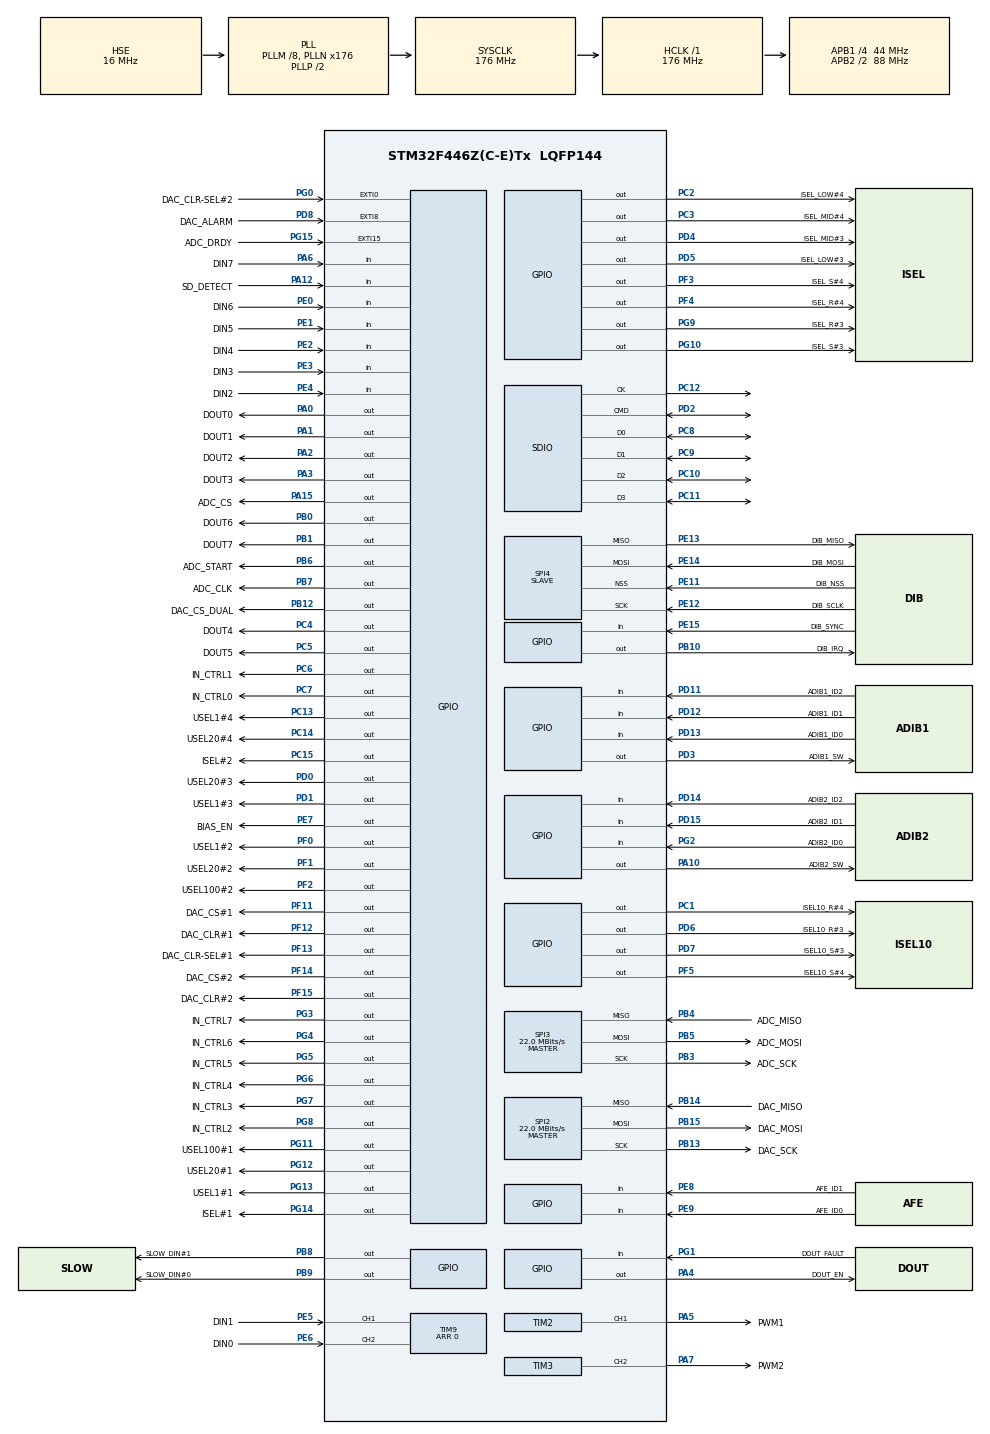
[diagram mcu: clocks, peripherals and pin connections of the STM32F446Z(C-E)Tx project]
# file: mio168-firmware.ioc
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Dma.SDIO_RX.4.MemBurst=DMA_MBURST_INC4
PD12.GPIO_Label=ADIB1_ID1
FATFS._USE_LFN=2
FATFS0.BSP.api=Unknown
NVIC.TIM6_DAC_IRQn=true\:0\:0\:false\:false\:true\:true\:true
PF14.PinState=GPIO_PIN_SET
PG8.Signal=GPIO_Output
Dma.SPI4_TX.1.PeriphDataAlignment=DMA_PDATAALIGN_BYTE
PG0.Signal=GPXTI0
PG15.GPIO_Label=ADC_DRDY
RCC.APB2TimFreq_Value=176000000
PB6.Signal=GPIO_Output
PC7.Signal=GPIO_Output
PB12.PinState=GPIO_PIN_SET
PD0.Signal=GPIO_Output
Dma.SPI3_RX.6.Direction=DMA_PERIPH_TO_MEMORY
PD8.Signal=GPXTI8
PE1.Signal=GPIO_Input
Dma.SPI4_RX.0.Priority=DMA_PRIORITY_LOW
FATFS0.BSP.ip=GPIO
NVIC.EXTI15_10_IRQn=true\:0\:0\:false\:false\:true\:true\:true
Dma.SPI2_RX.2.MemDataAlignment=DMA_MDATAALIGN_HALFWORD
Dma.SPI3_RX.6.Mode=DMA_NORMAL
PB3.Mode=Full_Duplex_Master
PF1.GPIO_Label=USEL20\#2
Dma.SPI2_RX.2.PeriphInc=DMA_PINC_DISABLE
PD1.GPIO_Label=USEL1\#3
PB12.GPIO_Label=DAC_CS_DUAL
PF12.GPIO_Label=DAC_CLR\#1
PC4.GPIO_Label=DOUT4
PE9.Signal=GPIO_Input
PB14.Mode=Full_Duplex_Master
PB1.GPIO_Label=DOUT7
PG4.GPIO_Label=IN_CTRL6
PE4.GPIO_Label=DIN2
PC9.Mode=SD_4_bits_Wide_bus
Dma.SPI2_RX.2.PeriphDataAlignment=DMA_PDATAALIGN_HALFWORD
PD14.GPIO_PuPd=GPIO_PULLUP
PE13.Mode=Full_Duplex_Slave
PG0.GPIO_PuPd=GPIO_PULLUP
Dma.SDIO_TX.5.PeriphDataAlignment=DMA_PDATAALIGN_WORD
Mcu.Package=LQFP144
PB9.Signal=GPIO_Output
PB1.Signal=GPIO_Output
SPI2.Mode=SPI_MODE_MASTER
Dma.SPI3_RX.6.MemInc=DMA_MINC_ENABLE
SPI3.Mode=SPI_MODE_MASTER
PD12.Signal=GPIO_Input
PA10.Signal=GPIO_Output
PE12.GPIO_Label=DIB_SCLK
TIM7.AutoReloadPreload=TIM_AUTORELOAD_PRELOAD_ENABLE
PC11.Mode=SD_4_bits_Wide_bus
RCC.APB2CLKDivider=RCC_HCLK_DIV2
Dma.SDIO_RX.4.PeriphDataAlignment=DMA_PDATAALIGN_WORD
RCC.APB1TimFreq_Value=88000000
PB13.Mode=Full_Duplex_Master
PA4.GPIO_Label=DOUT_EN
PD15.Signal=GPIO_Input
PG12.Signal=GPIO_Output
PE12.Mode=Full_Duplex_Slave
FATFS0.BSP.STBoard=false
Dma.SPI3_TX.7.MemInc=DMA_MINC_ENABLE
PG5.Signal=GPIO_Output
PC13.Signal=GPIO_Output
FATFS0.BSP.mode=Input
PD3.Signal=GPIO_Output
PC2.Signal=GPIO_Output
Dma.SDIO_TX.5.Direction=DMA_MEMORY_TO_PERIPH
PC14-OSC32_IN.Signal=GPIO_Output
Dma.SPI2_TX.3.PeriphDataAlignment=DMA_PDATAALIGN_HALFWORD
PB8.GPIO_Label=SLOW_DIN\#1
PE8.GPIO_Label=AFE_ID1
SDIO.ClockDiv=3
NVIC.DMA2_Stream6_IRQn=true\:0\:0\:false\:false\:true\:false\:true
PB14.Signal=SPI2_MISO
PA5.Signal=S_TIM2_CH1_ETR
PC12.Mode=SD_4_bits_Wide_bus
PE1.GPIO_Label=DIN5
PE14.Signal=SPI4_MOSI
PB4.GPIO_Label=ADC_MISO
PB15.GPIO_Label=DAC_MOSI
PG15.GPIO_ModeDefaultEXTI=GPIO_MODE_IT_FALLING
PG7.GPIO_Label=IN_CTRL3
PF4.GPIO_Label=ISEL_R\#4
PA1.GPIO_Label=DOUT1
SH.S_TIM9_CH1.0=TIM9_CH1,Input_Capture1_from_TI1
PF13.Signal=GPIO_Output
TIM2.Period=0
PC7.GPIO_Label=IN_CTRL0
PC8.Mode=SD_4_bits_Wide_bus
Dma.SDIO_RX.4.PeriphInc=DMA_PINC_DISABLE
PA5.GPIO_Label=PWM1
Dma.SDIO_RX.4.FIFOThreshold=DMA_FIFO_THRESHOLD_FULL
PE5.GPIO_Label=DIN1
ProjectManager.HeapSize=0x2000
NVIC.PriorityGroup=NVIC_PRIORITYGROUP_4
PF0.GPIO_Label=USEL1\#2
SDIO.HardwareFlowControl=SDIO_HARDWARE_FLOW_CONTROL_ENABLE
PE3.Signal=GPIO_Input
PF4.Signal=GPIO_Output
TIM9.Channel-Input_Capture2_from_TI2=TIM_CHANNEL_2
PD2.Signal=SDIO_CMD
FATFS0.BSP.name=Detect_SDIO
Mcu.Family=STM32F4
Dma.SDIO_TX.5.MemInc=DMA_MINC_ENABLE
PB10.PinState=GPIO_PIN_SET
Dma.SPI4_TX.1.MemDataAlignment=DMA_MDATAALIGN_BYTE
PG2.Signal=GPIO_Input
PE11.GPIO_Label=DIB_NSS
PD0.GPIO_Label=USEL20\#3
Dma.SPI3_TX.7.Priority=DMA_PRIORITY_LOW
PB13.GPIO_Label=DAC_SCK
PD8.GPIO_PuPd=GPIO_PULLUP
PG5.GPIO_Label=IN_CTRL5
Dma.SPI3_TX.7.FIFOMode=DMA_FIFOMODE_DISABLE
PB15.Signal=SPI2_MOSI
PG11.Signal=GPIO_Output
PG15.Signal=GPXTI15
Dma.SDIO_TX.5.FIFOThreshold=DMA_FIFO_THRESHOLD_FULL
PD13.Signal=GPIO_Input
Dma.SPI3_TX.7.Instance=DMA1_Stream5
PA15.GPIO_Label=ADC_CS
Dma.SDIO_RX.4.FIFOMode=DMA_FIFOMODE_ENABLE
TIM3.Period=0
PF13.GPIO_Speed=GPIO_SPEED_FREQ_VERY_HIGH
Dma.SPI4_TX.1.Direction=DMA_MEMORY_TO_PERIPH
TIM7.Period=999
Dma.SDIO_RX.4.MemDataAlignment=DMA_MDATAALIGN_WORD
Dma.SPI2_RX.2.Instance=DMA1_Stream3
RCC.HSE_VALUE=16000000
PA0-WKUP.GPIO_Speed=GPIO_SPEED_FREQ_LOW
RCC.RCC_MCO1Source=RCC_MCO1SOURCE_PLLCLK
PA14.Mode=Serial_Wire
PF11.Signal=GPIO_Output
PB5.Mode=Full_Duplex_Master
PB7.Signal=GPIO_Output
Dma.SDIO_RX.4.Mode=DMA_PFCTRL
TIM2.Channel-PWM\ Generation1\ CH1=TIM_CHANNEL_1
TIM7.TIM_MasterOutputTrigger=TIM_TRGO_RESET
PH1-OSC_OUT.Mode=HSE-External-Oscillator
PB7.GPIO_Label=ADC_CLK
PD13.GPIO_Label=ADIB1_ID0
PA6.Signal=GPIO_Input
PD5.GPIO_Label=ISEL_LOW\#3
PG1.GPIO_PuPd=GPIO_PULLUP
PA15.Signal=GPIO_Output
PG0.GPIO_Label=DAC_CLR-SEL\#2
Dma.SDIO_RX.4.Direction=DMA_PERIPH_TO_MEMORY
PB5.GPIO_Label=ADC_MOSI
Dma.Request2=SPI2_RX
Dma.Request1=SPI4_TX
Dma.Request4=SDIO_RX
Dma.Request3=SPI2_TX
Dma.SDIO_RX.4.Priority=DMA_PRIORITY_LOW
Dma.Request6=SPI3_RX
Dma.Request5=SDIO_TX
NVIC.DMA1_Stream0_IRQn=true\:0\:0\:true\:false\:true\:false\:true
PG11.GPIO_Label=USEL100\#1
PC5.Signal=GPIO_Output
PD3.GPIO_Label=ADIB1_SW
Dma.Request7=SPI3_TX
PE7.Signal=GPIO_Output
PD6.Signal=GPIO_Output
Dma.Request0=SPI4_RX
PF3.GPIO_Label=ISEL_S\#4
PE2.GPIO_Label=DIN4
Dma.SPI2_TX.3.Direction=DMA_MEMORY_TO_PERIPH
PB4.Signal=SPI3_MISO
PG2.GPIO_Label=ADIB2_ID0
PA3.Signal=GPIO_Output
Dma.SPI4_TX.1.MemInc=DMA_MINC_ENABLE
Dma.SDIO_TX.5.Mode=DMA_PFCTRL
Dma.SPI3_RX.6.FIFOMode=DMA_FIFOMODE_DISABLE
PD15.GPIO_Label=ADIB2_ID1
PG7.Signal=GPIO_Output
Dma.SPI2_TX.3.MemDataAlignment=DMA_MDATAALIGN_HALFWORD
PC11.Signal=SDIO_D3
PC8.Signal=SDIO_D0
TIM6.Prescaler=8
PC10.Mode=SD_4_bits_Wide_bus
VP_TIM6_VS_ClockSourceINT.Mode=Enable_Timer
PE14.GPIO_Label=DIB_MOSI
PA12.GPIO_Label=SD_DETECT
NVIC.SDIO_IRQn=true\:0\:0\:false\:false\:true\:true\:true
Dma.SDIO_RX.4.Instance=DMA2_Stream3
Dma.SPI2_RX.2.Mode=DMA_CIRCULAR
PD8.GPIO_Label=DAC_ALARM
FATFS0.BSP.instance=PA12
PG8.GPIO_Label=IN_CTRL2
PA13.Signal=SYS_JTMS-SWDIO
PB10.GPIO_Label=DIB_IRQ
Dma.SPI4_RX.0.PeriphDataAlignment=DMA_PDATAALIGN_BYTE
RCC.USBFreq_Value=25000000
PA1.Signal=GPIO_Output
PD2.Mode=SD_4_bits_Wide_bus
TIM7.Prescaler=8
board=custom
SPI3.CLKPhase=SPI_PHASE_2EDGE
RCC.VCOOutputFreq_Value=352000000
PB15.Mode=Full_Duplex_Master
Dma.SPI3_RX.6.PeriphDataAlignment=DMA_PDATAALIGN_BYTE
PA15.PinState=GPIO_PIN_SET
PC1.GPIO_Label=ISEL10_R\#4
PF15.GPIO_Label=DAC_CLR\#2
PF1.Signal=GPIO_Output
PE0.Signal=GPIO_Input
PE7.GPIO_Label=BIAS_EN
PE12.Signal=SPI4_SCK
RCC.SYSCLKFreq_VALUE=176000000
Dma.SPI3_RX.6.Instance=DMA1_Stream0
Dma.SPI4_RX.0.Direction=DMA_PERIPH_TO_MEMORY
PA15.GPIO_Speed=GPIO_SPEED_FREQ_LOW
Dma.SDIO_TX.5.FIFOMode=DMA_FIFOMODE_ENABLE
RCC.PLLQ=8
RCC.PLLM=8
RCC.PLLN=176
Dma.SPI3_TX.7.PeriphInc=DMA_PINC_DISABLE
NVIC.DMA1_Stream3_IRQn=true\:0\:0\:false\:false\:true\:false\:false
Dma.SDIO_RX.4.PeriphBurst=DMA_PBURST_INC4
VP_CRC_VS_CRC.Mode=CRC_Activate
Dma.SDIO_TX.5.Instance=DMA2_Stream6
PB12.Signal=GPIO_Output
PA3.GPIO_Label=DOUT3
Dma.SPI3_TX.7.PeriphDataAlignment=DMA_PDATAALIGN_BYTE
PH0-OSC_IN.Signal=RCC_OSC_IN
SPI3.Direction=SPI_DIRECTION_2LINES
SPI4.VirtualType=VM_SLAVE
SPI3.VirtualType=VM_MASTER
PG2.GPIO_PuPd=GPIO_PULLUP
SPI2.VirtualType=VM_MASTER
VP_FATFS_VS_SDIO.Mode=SDIO
PG4.Signal=GPIO_Output
PC12.Signal=SDIO_CK
PB14.GPIO_Label=DAC_MISO
PG6.GPIO_Label=IN_CTRL4
PE8.GPIO_PuPd=GPIO_PULLUP
PC6.GPIO_Label=IN_CTRL1
PA6.GPIO_Label=DIN7
PB6.GPIO_Label=ADC_START
PB13.Signal=SPI2_SCK
PD6.GPIO_Label=ISEL10_R\#3
PG13.Signal=GPIO_Output
PC15-OSC32_OUT.GPIO_Label=ISEL\#2
PE6.GPIO_Label=DIN0
RCC.SYSCLKSource=RCC_SYSCLKSOURCE_PLLCLK
Dma.SPI3_RX.6.PeriphInc=DMA_PINC_DISABLE
Dma.SPI3_TX.7.MemDataAlignment=DMA_MDATAALIGN_BYTE
Dma.SPI2_RX.2.Direction=DMA_PERIPH_TO_MEMORY
PD4.Signal=GPIO_Output
PC3.Signal=GPIO_Output
PE5.Signal=S_TIM9_CH1
FATFS0.BSP.i2caddr=0
SPI2.CalculateBaudRate=22.0 MBits/s
PE2.Signal=GPIO_Input
PF3.Signal=GPIO_Output
Dma.SPI4_RX.0.Mode=DMA_NORMAL
PB7.PinState=GPIO_PIN_SET
FATFS0.BSP.solution=PA12
Dma.SPI2_RX.2.MemInc=DMA_MINC_ENABLE
Dma.SDIO_TX.5.PeriphInc=DMA_PINC_DISABLE
PF14.Signal=GPIO_Output
PA12.GPIO_PuPd=GPIO_PULLUP
TIM9.Period=0
Dma.SPI2_TX.3.MemInc=DMA_MINC_ENABLE
Dma.SPI3_RX.6.Priority=DMA_PRIORITY_LOW
Dma.SPI3_TX.7.Direction=DMA_MEMORY_TO_PERIPH
Dma.SDIO_TX.5.MemDataAlignment=DMA_MDATAALIGN_WORD
PG9.Signal=GPIO_Output
PC6.Signal=GPIO_Output
PD7.Signal=GPIO_Output
PD1.Signal=GPIO_Output
PF14.GPIO_Label=DAC_CS\#2
PF13.PinState=GPIO_PIN_SET
NVIC.DMA2_Stream1_IRQn=true\:0\:0\:true\:false\:true\:false\:true
RCC.APB1CLKDivider=RCC_HCLK_DIV4
Dma.SPI3_RX.6.MemDataAlignment=DMA_MDATAALIGN_BYTE
PF13.GPIO_Label=DAC_CLR-SEL\#1
PG13.GPIO_Label=USEL1\#1
PA0-WKUP.GPIO_Label=DOUT0
PA0-WKUP.Signal=GPIO_Output
PG10.Signal=GPIO_Output
Dma.SPI4_TX.1.PeriphInc=DMA_PINC_DISABLE
Dma.SPI2_RX.2.FIFOMode=DMA_FIFOMODE_DISABLE
SH.S_TIM9_CH2.0=TIM9_CH2,Input_Capture2_from_TI2
Dma.SPI3_TX.7.Mode=DMA_NORMAL
SPI2.CRCCalculation=SPI_CRCCALCULATION_DISABLE
Dma.SPI2_TX.3.Mode=DMA_CIRCULAR
SPI4.VirtualNSS=VM_NSSHARD
PE9.GPIO_Label=AFE_ID0
Dma.SDIO_TX.5.Priority=DMA_PRIORITY_LOW
PB10.Signal=GPIO_Output
FATFS.BSP.number=1
RCC.USBCLockSelection=RCC_CLK48CLKSOURCE_PLLSAIP
Dma.SPI2_TX.3.Instance=DMA1_Stream4
PE15.Signal=GPIO_Input
PE8.Signal=GPIO_Input
PA13.Mode=Serial_Wire
PG14.GPIO_Label=ISEL\#1
PA4.Signal=GPIO_Output
PB5.Signal=SPI3_MOSI
PE13.GPIO_Label=DIB_MISO
PD11.Signal=GPIO_Input
SH.S_TIM2_CH1_ETR.0=TIM2_CH1,PWM Generation1 CH1
Dma.SDIO_TX.5.MemBurst=DMA_MBURST_INC4
Dma.SPI4_TX.1.Priority=DMA_PRIORITY_LOW
TIM3.Channel-PWM\ Generation2\ CH2=TIM_CHANNEL_2
Dma.SPI2_TX.3.PeriphInc=DMA_PINC_DISABLE
PC3.GPIO_Label=ISEL_MID\#4
SPI2.DataSize=SPI_DATASIZE_8BIT
Dma.SPI2_TX.3.FIFOMode=DMA_FIFOMODE_DISABLE
PG3.GPIO_Label=IN_CTRL7
PB0.Signal=GPIO_Output
Dma.SPI4_RX.0.MemDataAlignment=DMA_MDATAALIGN_BYTE
PC1.Signal=GPIO_Output
PG15.GPIO_PuPd=GPIO_PULLUP
PG10.GPIO_Label=ISEL_S\#3
RCC.CortexFreq_Value=176000000
PG6.Signal=GPIO_Output
PC10.Signal=SDIO_D2
SPI4.Direction=SPI_DIRECTION_2LINES
PB0.GPIO_Label=DOUT6
PC13.GPIO_Label=USEL1\#4
NVIC.DMA1_Stream4_IRQn=true\:0\:0\:false\:false\:true\:false\:false
ProjectManager.StackSize=0x4000
VP_TIM7_VS_ClockSourceINT.Mode=Enable_Timer
PD11.GPIO_PuPd=GPIO_PULLUP
Dma.SPI4_RX.0.MemInc=DMA_MINC_ENABLE
PA12.Signal=GPIO_Input
PE11.Mode=NSS_Signal_Hard_Input
SPI4.Mode=SPI_MODE_SLAVE
PD11.GPIO_Label=ADIB1_ID2
RCC.HCLKFreq_Value=176000000
PF11.GPIO_Label=DAC_CS\#1
PF12.Signal=GPIO_Output
Dma.SPI2_TX.3.Priority=DMA_PRIORITY_LOW
NVIC.DMA2_Stream0_IRQn=true\:0\:0\:true\:false\:true\:false\:true
RCC.AHBFreq_Value=176000000
SPI2.BaudRatePrescaler=SPI_BAUDRATEPRESCALER_2
PH0-OSC_IN.Mode=HSE-External-Oscillator
SPI3.DataSize=SPI_DATASIZE_8BIT
SPI4.CRCPolynomial=X0+X1+X2
PB4.Mode=Full_Duplex_Master
PE13.Signal=SPI4_MISO
PA10.GPIO_Label=ADIB2_SW
Dma.SPI4_TX.1.Instance=DMA2_Stream1
PF11.PinState=GPIO_PIN_SET
RCC.RCC_MCODiv1=RCC_MCODIV_4
TIM6.Period=999
PE4.Signal=GPIO_Input
PD7.GPIO_Label=ISEL10_S\#3
Dma.SPI2_RX.2.Priority=DMA_PRIORITY_LOW
PA2.GPIO_Label=DOUT2
PD15.GPIO_PuPd=GPIO_PULLUP
PF5.GPIO_Label=ISEL10_S\#4
SPI2.CLKPhase=SPI_PHASE_1EDGE
PE0.GPIO_Label=DIN6
RCC.PLLSAIN=50
PF5.Signal=GPIO_Output
RCC.PLLSAIM=8
RCC.PLLSAIP=RCC_PLLSAIP_DIV4
Dma.SPI4_RX.0.PeriphInc=DMA_PINC_DISABLE
PC14-OSC32_IN.GPIO_Label=USEL20\#4
SPI2.Direction=SPI_DIRECTION_2LINES
PF0.Signal=GPIO_Output
PC2.GPIO_Label=ISEL_LOW\#4
NVIC.TIM7_IRQn=true\:0\:0\:true\:false\:true\:true\:true
PB3.GPIO_Label=ADC_SCK
RCC.PLLSourceVirtual=RCC_PLLSOURCE_HSE
Dma.SPI4_TX.1.Mode=DMA_NORMAL
PB9.GPIO_Label=SLOW_DIN\#0
PG3.Signal=GPIO_Output
PG1.Signal=GPIO_Input
PC4.Signal=GPIO_Output
PD5.Signal=GPIO_Output
SDIO.ClockBypass=SDIO_CLOCK_BYPASS_ENABLE
Dma.SDIO_RX.4.MemInc=DMA_MINC_ENABLE
TIM6.AutoReloadPreload=TIM_AUTORELOAD_PRELOAD_ENABLE
Dma.SPI4_TX.1.FIFOMode=DMA_FIFOMODE_DISABLE
PE15.GPIO_Label=DIB_SYNC
ProjectManager.TargetToolchain=STM32CubeIDE
NVIC.DMA1_Stream5_IRQn=true\:0\:0\:true\:false\:true\:false\:true
PF2.Signal=GPIO_Output
NVIC.DMA2_Stream3_IRQn=true\:0\:0\:false\:false\:true\:false\:true
PE11.Signal=SPI4_NSS
PC15-OSC32_OUT.Signal=GPIO_Output
TIM9.Channel-Input_Capture1_from_TI1=TIM_CHANNEL_1
SPI4.CRCCalculation=SPI_CRCCALCULATION_ENABLE
PG9.GPIO_Label=ISEL_R\#3
SH.S_TIM3_CH2.0=TIM3_CH2,PWM Generation2 CH2
PG14.Signal=GPIO_Output
PG1.GPIO_Label=DOUT_FAULT
RCC.APB2Freq_Value=88000000
SPI3.CalculateBaudRate=22.0 MBits/s
PD4.GPIO_Label=ISEL_MID\#3
PE14.Mode=Full_Duplex_Slave
SPI3.BaudRatePrescaler=SPI_BAUDRATEPRESCALER_2
PH1-OSC_OUT.Signal=RCC_OSC_OUT
PD13.GPIO_PuPd=GPIO_PULLUP
PF15.Signal=GPIO_Output
PD14.GPIO_Label=ADIB2_ID2
PE6.Signal=S_TIM9_CH2
Mcu.Name=STM32F446Z(C-E)Tx
PA2.Signal=GPIO_Output
PD14.Signal=GPIO_Input
PB3.Signal=SPI3_SCK
PA7.GPIO_Label=PWM2
Dma.SDIO_TX.5.PeriphBurst=DMA_PBURST_INC4
PC5.GPIO_Label=DOUT5
Dma.SPI4_RX.0.Instance=DMA2_Stream0
PA14.Signal=SYS_JTCK-SWCLK
PG12.GPIO_Label=USEL20\#1
PB8.Signal=GPIO_Output
PE3.GPIO_Label=DIN3
PC9.Signal=SDIO_D1
RCC.APB1Freq_Value=44000000
SPI2.TIMode=SPI_TIMODE_DISABLE
PD12.GPIO_PuPd=GPIO_PULLUP
PA7.Signal=S_TIM3_CH2
PE9.GPIO_PuPd=GPIO_PULLUP
PF2.GPIO_Label=USEL100\#2
Dma.SPI4_RX.0.FIFOMode=DMA_FIFOMODE_DISABLE

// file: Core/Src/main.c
/* USER CODE BEGIN Header */
/**
  ******************************************************************************
  * @file           : main.c
  * @brief          : Main program body
  ******************************************************************************
  * @attention
  *
  * <h2><center>&copy; Copyright (c) 2020 STMicroelectronics.
  * All rights reserved.</center></h2>
  *
  * This software component is licensed by ST under BSD 3-Clause license,
  * the "License"; You may not use this file except in compliance with the
  * License. You may obtain a copy of the License at:
  *                        opensource.org/licenses/BSD-3-Clause
  *
  ******************************************************************************
  */
/* USER CODE END Header */
#include "main.h"
#include "fatfs.h"

/* USER CODE BEGIN Includes */
#include <stdio.h>
#include <string.h>

/* USER CODE END Includes */

CRC_HandleTypeDef hcrc;

SD_HandleTypeDef hsd;
DMA_HandleTypeDef hdma_sdio_rx;
DMA_HandleTypeDef hdma_sdio_tx;

SPI_HandleTypeDef hspi2;
SPI_HandleTypeDef hspi3;
SPI_HandleTypeDef hspi4;
DMA_HandleTypeDef hdma_spi2_rx;
DMA_HandleTypeDef hdma_spi2_tx;
DMA_HandleTypeDef hdma_spi3_rx;
DMA_HandleTypeDef hdma_spi3_tx;
DMA_HandleTypeDef hdma_spi4_rx;
DMA_HandleTypeDef hdma_spi4_tx;

TIM_HandleTypeDef htim2;
TIM_HandleTypeDef htim3;
TIM_HandleTypeDef htim6;
TIM_HandleTypeDef htim7;
TIM_HandleTypeDef htim9;

void SystemClock_Config(void);
static void MX_GPIO_Init(void);
static void MX_DMA_Init(void);
static void MX_SDIO_SD_Init(void);
static void MX_SPI4_Init(void);
static void MX_CRC_Init(void);
static void MX_SPI2_Init(void);
static void MX_SPI3_Init(void);
static void MX_TIM9_Init(void);
static void MX_TIM6_Init(void);
static void MX_TIM2_Init(void);
static void MX_TIM3_Init(void);
static void MX_TIM7_Init(void);
/* USER CODE BEGIN PFP */

#if 0
char buffer[65536];

static void testSdCard(uint32_t chunkSize) {
	if (f_mount(&SDFatFS, (TCHAR const*)SDPath, 1) != FR_OK) {
		/* FatFs Initialization Error */
		return;
	}

	char filePath[128];

	sprintf(filePath, "BMRK%d.TXT", (int)chunkSize);

	if (f_open(&SDFile, filePath, FA_CREATE_ALWAYS | FA_WRITE) != FR_OK) {
		return;
	}

	for (int i = 0; i < chunkSize - 1; i++) {
		buffer[i] = 32 + i % (127 - 32);
	}
	buffer[chunkSize - 1] = '\n';

	uint32_t startTime = HAL_GetTick();

	uint32_t transferred = 0;

	int numSteps = (10 * 1024 * 1024) / chunkSize;

	for (int i = 0; i < numSteps; i++) {
		UINT byteswritten;
		FRESULT res = f_write(&SDFile, buffer, chunkSize, (void *)&byteswritten);
		transferred += byteswritten;
		if ((byteswritten < chunkSize) || (res != FR_OK)) {
			break;
		}
	}

	uint32_t endTime = HAL_GetTick();

	uint32_t diffMs = endTime - startTime;

	double diffS = (endTime - startTime) / 1000.0;

	sprintf(buffer, "startTime=%lu\nendTime=%lu\ndiffMs=%lu\ndiffS=%f\ntransferred=%lu\nspeed=%f\n",
			startTime, endTime, diffMs, diffS, transferred, transferred / diffS);
	UINT byteswritten;
	f_write(&SDFile, buffer, strlen(buffer), (void *)&byteswritten);

	f_close(&SDFile);
}
#endif

void TIM2_Init(void) {
	MX_TIM2_Init();
}

void TIM3_Init(void) {
	MX_TIM3_Init();
}

void SPI4_Init(void) {
	MX_SPI4_Init();
}

/* USER CODE END PFP */

/* USER CODE BEGIN 0 */
void setup();
void loop();
/* USER CODE END 0 */

int main(void)
{

  /* MCU Configuration--------------------------------------------------------*/

  /* Reset of all peripherals, Initializes the Flash interface and the Systick. */
  HAL_Init();

  /* Configure the system clock */
  SystemClock_Config();

  /* Initialize all configured peripherals */
  MX_GPIO_Init();
  MX_DMA_Init();
  MX_SDIO_SD_Init();
  MX_SPI4_Init();
  MX_CRC_Init();
  MX_SPI2_Init();
  MX_SPI3_Init();
  MX_TIM9_Init();
  MX_FATFS_Init();
  MX_TIM6_Init();
  MX_TIM2_Init();
  MX_TIM3_Init();
  MX_TIM7_Init();
  /* USER CODE BEGIN 2 */

#if 0
  testSdCard(512);
  testSdCard(1024);
  testSdCard(2048);
  testSdCard(4096);
  testSdCard(8192);
  testSdCard(8192);
  testSdCard(16384);
  testSdCard(32768);
  testSdCard(65536);
#endif

  setup();
  /* USER CODE END 2 */

  /* Infinite loop */
  while (1)
  {

    /* USER CODE BEGIN 3 */
	  loop();
  }
  /* USER CODE END 3 */
}

void SystemClock_Config(void)
{
  RCC_OscInitTypeDef RCC_OscInitStruct = {0};
  RCC_ClkInitTypeDef RCC_ClkInitStruct = {0};
  RCC_PeriphCLKInitTypeDef PeriphClkInitStruct = {0};

  /** Configure the main internal regulator output voltage
  */
  __HAL_RCC_PWR_CLK_ENABLE();
  __HAL_PWR_VOLTAGESCALING_CONFIG(PWR_REGULATOR_VOLTAGE_SCALE1);
  /** Initializes the RCC Oscillators according to the specified parameters
  * in the RCC_OscInitTypeDef structure.
  */
  RCC_OscInitStruct.OscillatorType = RCC_OSCILLATORTYPE_HSE;
  RCC_OscInitStruct.HSEState = RCC_HSE_ON;
  RCC_OscInitStruct.PLL.PLLState = RCC_PLL_ON;
  RCC_OscInitStruct.PLL.PLLSource = RCC_PLLSOURCE_HSE;
  RCC_OscInitStruct.PLL.PLLM = 8;
  RCC_OscInitStruct.PLL.PLLN = 176;
  RCC_OscInitStruct.PLL.PLLP = RCC_PLLP_DIV2;
  RCC_OscInitStruct.PLL.PLLQ = 8;
  RCC_OscInitStruct.PLL.PLLR = 2;
  if (HAL_RCC_OscConfig(&RCC_OscInitStruct) != HAL_OK)
  {
    Error_Handler();
  }
  /** Activate the Over-Drive mode
  */
  if (HAL_PWREx_EnableOverDrive() != HAL_OK)
  {
    Error_Handler();
  }
  /** Initializes the CPU, AHB and APB buses clocks
  */
  RCC_ClkInitStruct.ClockType = RCC_CLOCKTYPE_HCLK|RCC_CLOCKTYPE_SYSCLK
                              |RCC_CLOCKTYPE_PCLK1|RCC_CLOCKTYPE_PCLK2;
  RCC_ClkInitStruct.SYSCLKSource = RCC_SYSCLKSOURCE_PLLCLK;
  RCC_ClkInitStruct.AHBCLKDivider = RCC_SYSCLK_DIV1;
  RCC_ClkInitStruct.APB1CLKDivider = RCC_HCLK_DIV4;
  RCC_ClkInitStruct.APB2CLKDivider = RCC_HCLK_DIV2;

  if (HAL_RCC_ClockConfig(&RCC_ClkInitStruct, FLASH_LATENCY_5) != HAL_OK)
  {
    Error_Handler();
  }
  PeriphClkInitStruct.PeriphClockSelection = RCC_PERIPHCLK_SDIO|RCC_PERIPHCLK_CLK48;
  PeriphClkInitStruct.PLLSAI.PLLSAIM = 8;
  PeriphClkInitStruct.PLLSAI.PLLSAIN = 50;
  PeriphClkInitStruct.PLLSAI.PLLSAIQ = 2;
  PeriphClkInitStruct.PLLSAI.PLLSAIP = RCC_PLLSAIP_DIV4;
  PeriphClkInitStruct.PLLSAIDivQ = 1;
  PeriphClkInitStruct.Clk48ClockSelection = RCC_CLK48CLKSOURCE_PLLSAIP;
  PeriphClkInitStruct.SdioClockSelection = RCC_SDIOCLKSOURCE_CLK48;
  if (HAL_RCCEx_PeriphCLKConfig(&PeriphClkInitStruct) != HAL_OK)
  {
    Error_Handler();
  }
}

static void MX_CRC_Init(void)
{

  hcrc.Instance = CRC;
  if (HAL_CRC_Init(&hcrc) != HAL_OK)
  {
    Error_Handler();
  }

}

static void MX_SDIO_SD_Init(void)
{

  hsd.Instance = SDIO;
  hsd.Init.ClockEdge = SDIO_CLOCK_EDGE_RISING;
  hsd.Init.ClockBypass = SDIO_CLOCK_BYPASS_ENABLE;
  hsd.Init.ClockPowerSave = SDIO_CLOCK_POWER_SAVE_DISABLE;
  hsd.Init.BusWide = SDIO_BUS_WIDE_1B;
  hsd.Init.HardwareFlowControl = SDIO_HARDWARE_FLOW_CONTROL_ENABLE;
  hsd.Init.ClockDiv = 3;

}

static void MX_SPI2_Init(void)
{

  /* SPI2 parameter configuration*/
  hspi2.Instance = SPI2;
  hspi2.Init.Mode = SPI_MODE_MASTER;
  hspi2.Init.Direction = SPI_DIRECTION_2LINES;
  hspi2.Init.DataSize = SPI_DATASIZE_8BIT;
  hspi2.Init.CLKPolarity = SPI_POLARITY_LOW;
  hspi2.Init.CLKPhase = SPI_PHASE_1EDGE;
  hspi2.Init.NSS = SPI_NSS_SOFT;
  hspi2.Init.BaudRatePrescaler = SPI_BAUDRATEPRESCALER_2;
  hspi2.Init.FirstBit = SPI_FIRSTBIT_MSB;
  hspi2.Init.TIMode = SPI_TIMODE_DISABLE;
  hspi2.Init.CRCCalculation = SPI_CRCCALCULATION_DISABLE;
  hspi2.Init.CRCPolynomial = 10;
  if (HAL_SPI_Init(&hspi2) != HAL_OK)
  {
    Error_Handler();
  }

}

static void MX_SPI3_Init(void)
{

  /* SPI3 parameter configuration*/
  hspi3.Instance = SPI3;
  hspi3.Init.Mode = SPI_MODE_MASTER;
  hspi3.Init.Direction = SPI_DIRECTION_2LINES;
  hspi3.Init.DataSize = SPI_DATASIZE_8BIT;
  hspi3.Init.CLKPolarity = SPI_POLARITY_LOW;
  hspi3.Init.CLKPhase = SPI_PHASE_2EDGE;
  hspi3.Init.NSS = SPI_NSS_SOFT;
  hspi3.Init.BaudRatePrescaler = SPI_BAUDRATEPRESCALER_2;
  hspi3.Init.FirstBit = SPI_FIRSTBIT_MSB;
  hspi3.Init.TIMode = SPI_TIMODE_DISABLE;
  hspi3.Init.CRCCalculation = SPI_CRCCALCULATION_DISABLE;
  hspi3.Init.CRCPolynomial = 10;
  if (HAL_SPI_Init(&hspi3) != HAL_OK)
  {
    Error_Handler();
  }

}

static void MX_SPI4_Init(void)
{

  /* SPI4 parameter configuration*/
  hspi4.Instance = SPI4;
  hspi4.Init.Mode = SPI_MODE_SLAVE;
  hspi4.Init.Direction = SPI_DIRECTION_2LINES;
  hspi4.Init.DataSize = SPI_DATASIZE_8BIT;
  hspi4.Init.CLKPolarity = SPI_POLARITY_LOW;
  hspi4.Init.CLKPhase = SPI_PHASE_1EDGE;
  hspi4.Init.NSS = SPI_NSS_HARD_INPUT;
  hspi4.Init.FirstBit = SPI_FIRSTBIT_MSB;
  hspi4.Init.TIMode = SPI_TIMODE_DISABLE;
  hspi4.Init.CRCCalculation = SPI_CRCCALCULATION_ENABLE;
  hspi4.Init.CRCPolynomial = 7;
  if (HAL_SPI_Init(&hspi4) != HAL_OK)
  {
    Error_Handler();
  }

}

static void MX_TIM2_Init(void)
{

  TIM_MasterConfigTypeDef sMasterConfig = {0};
  TIM_OC_InitTypeDef sConfigOC = {0};

  htim2.Instance = TIM2;
  htim2.Init.Prescaler = 0;
  htim2.Init.CounterMode = TIM_COUNTERMODE_UP;
  htim2.Init.Period = 0;
  htim2.Init.ClockDivision = TIM_CLOCKDIVISION_DIV1;
  htim2.Init.AutoReloadPreload = TIM_AUTORELOAD_PRELOAD_DISABLE;
  if (HAL_TIM_PWM_Init(&htim2) != HAL_OK)
  {
    Error_Handler();
  }
  sMasterConfig.MasterOutputTrigger = TIM_TRGO_RESET;
  sMasterConfig.MasterSlaveMode = TIM_MASTERSLAVEMODE_DISABLE;
  if (HAL_TIMEx_MasterConfigSynchronization(&htim2, &sMasterConfig) != HAL_OK)
  {
    Error_Handler();
  }
  sConfigOC.OCMode = TIM_OCMODE_PWM1;
  sConfigOC.Pulse = 0;
  sConfigOC.OCPolarity = TIM_OCPOLARITY_HIGH;
  sConfigOC.OCFastMode = TIM_OCFAST_DISABLE;
  if (HAL_TIM_PWM_ConfigChannel(&htim2, &sConfigOC, TIM_CHANNEL_1) != HAL_OK)
  {
    Error_Handler();
  }
  HAL_TIM_MspPostInit(&htim2);

}

static void MX_TIM3_Init(void)
{

  TIM_MasterConfigTypeDef sMasterConfig = {0};
  TIM_OC_InitTypeDef sConfigOC = {0};

  htim3.Instance = TIM3;
  htim3.Init.Prescaler = 0;
  htim3.Init.CounterMode = TIM_COUNTERMODE_UP;
  htim3.Init.Period = 0;
  htim3.Init.ClockDivision = TIM_CLOCKDIVISION_DIV1;
  htim3.Init.AutoReloadPreload = TIM_AUTORELOAD_PRELOAD_DISABLE;
  if (HAL_TIM_PWM_Init(&htim3) != HAL_OK)
  {
    Error_Handler();
  }
  sMasterConfig.MasterOutputTrigger = TIM_TRGO_RESET;
  sMasterConfig.MasterSlaveMode = TIM_MASTERSLAVEMODE_DISABLE;
  if (HAL_TIMEx_MasterConfigSynchronization(&htim3, &sMasterConfig) != HAL_OK)
  {
    Error_Handler();
  }
  sConfigOC.OCMode = TIM_OCMODE_PWM1;
  sConfigOC.Pulse = 0;
  sConfigOC.OCPolarity = TIM_OCPOLARITY_HIGH;
  sConfigOC.OCFastMode = TIM_OCFAST_DISABLE;
  if (HAL_TIM_PWM_ConfigChannel(&htim3, &sConfigOC, TIM_CHANNEL_2) != HAL_OK)
  {
    Error_Handler();
  }
  HAL_TIM_MspPostInit(&htim3);

}

static void MX_TIM6_Init(void)
{

  TIM_MasterConfigTypeDef sMasterConfig = {0};

  htim6.Instance = TIM6;
  htim6.Init.Prescaler = 8;
  htim6.Init.CounterMode = TIM_COUNTERMODE_UP;
  htim6.Init.Period = 999;
  htim6.Init.AutoReloadPreload = TIM_AUTORELOAD_PRELOAD_ENABLE;
  if (HAL_TIM_Base_Init(&htim6) != HAL_OK)
  {
    Error_Handler();
  }
  sMasterConfig.MasterOutputTrigger = TIM_TRGO_RESET;
  sMasterConfig.MasterSlaveMode = TIM_MASTERSLAVEMODE_DISABLE;
  if (HAL_TIMEx_MasterConfigSynchronization(&htim6, &sMasterConfig) != HAL_OK)
  {
    Error_Handler();
  }

}

static void MX_TIM7_Init(void)
{

  TIM_MasterConfigTypeDef sMasterConfig = {0};

  htim7.Instance = TIM7;
  htim7.Init.Prescaler = 8;
  htim7.Init.CounterMode = TIM_COUNTERMODE_UP;
  htim7.Init.Period = 999;
  htim7.Init.AutoReloadPreload = TIM_AUTORELOAD_PRELOAD_ENABLE;
  if (HAL_TIM_Base_Init(&htim7) != HAL_OK)
  {
    Error_Handler();
  }
  sMasterConfig.MasterOutputTrigger = TIM_TRGO_RESET;
  sMasterConfig.MasterSlaveMode = TIM_MASTERSLAVEMODE_DISABLE;
  if (HAL_TIMEx_MasterConfigSynchronization(&htim7, &sMasterConfig) != HAL_OK)
  {
    Error_Handler();
  }

}

static void MX_TIM9_Init(void)
{

  TIM_IC_InitTypeDef sConfigIC = {0};

  htim9.Instance = TIM9;
  htim9.Init.Prescaler = 0;
  htim9.Init.CounterMode = TIM_COUNTERMODE_UP;
  htim9.Init.Period = 0;
  htim9.Init.ClockDivision = TIM_CLOCKDIVISION_DIV1;
  htim9.Init.AutoReloadPreload = TIM_AUTORELOAD_PRELOAD_DISABLE;
  if (HAL_TIM_IC_Init(&htim9) != HAL_OK)
  {
    Error_Handler();
  }
  sConfigIC.ICPolarity = TIM_INPUTCHANNELPOLARITY_RISING;
  sConfigIC.ICSelection = TIM_ICSELECTION_DIRECTTI;
  sConfigIC.ICPrescaler = TIM_ICPSC_DIV1;
  sConfigIC.ICFilter = 0;
  if (HAL_TIM_IC_ConfigChannel(&htim9, &sConfigIC, TIM_CHANNEL_1) != HAL_OK)
  {
    Error_Handler();
  }
  if (HAL_TIM_IC_ConfigChannel(&htim9, &sConfigIC, TIM_CHANNEL_2) != HAL_OK)
  {
    Error_Handler();
  }

}

static void MX_DMA_Init(void)
{

  /* DMA controller clock enable */
  __HAL_RCC_DMA2_CLK_ENABLE();
  __HAL_RCC_DMA1_CLK_ENABLE();

  /* DMA interrupt init */
  /* DMA1_Stream0_IRQn interrupt configuration */
  HAL_NVIC_SetPriority(DMA1_Stream0_IRQn, 0, 0);
  HAL_NVIC_EnableIRQ(DMA1_Stream0_IRQn);
  /* DMA1_Stream3_IRQn interrupt configuration */
  HAL_NVIC_SetPriority(DMA1_Stream3_IRQn, 0, 0);
  HAL_NVIC_EnableIRQ(DMA1_Stream3_IRQn);
  /* DMA1_Stream4_IRQn interrupt configuration */
  HAL_NVIC_SetPriority(DMA1_Stream4_IRQn, 0, 0);
  HAL_NVIC_EnableIRQ(DMA1_Stream4_IRQn);
  /* DMA1_Stream5_IRQn interrupt configuration */
  HAL_NVIC_SetPriority(DMA1_Stream5_IRQn, 0, 0);
  HAL_NVIC_EnableIRQ(DMA1_Stream5_IRQn);
  /* DMA2_Stream0_IRQn interrupt configuration */
  HAL_NVIC_SetPriority(DMA2_Stream0_IRQn, 0, 0);
  HAL_NVIC_EnableIRQ(DMA2_Stream0_IRQn);
  /* DMA2_Stream1_IRQn interrupt configuration */
  HAL_NVIC_SetPriority(DMA2_Stream1_IRQn, 0, 0);
  HAL_NVIC_EnableIRQ(DMA2_Stream1_IRQn);
  /* DMA2_Stream3_IRQn interrupt configuration */
  HAL_NVIC_SetPriority(DMA2_Stream3_IRQn, 0, 0);
  HAL_NVIC_EnableIRQ(DMA2_Stream3_IRQn);
  /* DMA2_Stream6_IRQn interrupt configuration */
  HAL_NVIC_SetPriority(DMA2_Stream6_IRQn, 0, 0);
  HAL_NVIC_EnableIRQ(DMA2_Stream6_IRQn);

}

static void MX_GPIO_Init(void)
{
  GPIO_InitTypeDef GPIO_InitStruct = {0};

  /* GPIO Ports Clock Enable */
  __HAL_RCC_GPIOE_CLK_ENABLE();
  __HAL_RCC_GPIOC_CLK_ENABLE();
  __HAL_RCC_GPIOF_CLK_ENABLE();
  __HAL_RCC_GPIOH_CLK_ENABLE();
  __HAL_RCC_GPIOA_CLK_ENABLE();
  __HAL_RCC_GPIOB_CLK_ENABLE();
  __HAL_RCC_GPIOG_CLK_ENABLE();
  __HAL_RCC_GPIOD_CLK_ENABLE();

  /*Configure GPIO pin Output Level */
  HAL_GPIO_WritePin(GPIOC, USEL1_4_Pin|USEL20_4_Pin|ISEL_2_Pin|ISEL10_R_4_Pin
                          |ISEL_LOW_4_Pin|ISEL_MID_4_Pin|DOUT4_Pin|DOUT5_Pin
                          |IN_CTRL1_Pin|IN_CTRL0_Pin, GPIO_PIN_RESET);

  /*Configure GPIO pin Output Level */
  HAL_GPIO_WritePin(GPIOF, USEL1_2_Pin|USEL20_2_Pin|USEL100_2_Pin|ISEL_S_4_Pin
                          |ISEL_R_4_Pin|ISEL10_S_4_Pin|DAC_CLR_1_Pin|DAC_CLR_2_Pin, GPIO_PIN_RESET);

  /*Configure GPIO pin Output Level */
  HAL_GPIO_WritePin(GPIOA, DOUT0_Pin|DOUT1_Pin|DOUT2_Pin|DOUT3_Pin
                          |DOUT_EN_Pin|ADIB2_SW_Pin, GPIO_PIN_RESET);

  /*Configure GPIO pin Output Level */
  HAL_GPIO_WritePin(GPIOB, DOUT6_Pin|DOUT7_Pin|ADC_START_Pin|SLOW_DIN_1_Pin
                          |SLOW_DIN_0_Pin, GPIO_PIN_RESET);

  /*Configure GPIO pin Output Level */
  HAL_GPIO_WritePin(GPIOF, DAC_CS_1_Pin|DAC_CLR_SEL_1_Pin|DAC_CS_2_Pin, GPIO_PIN_SET);

  /*Configure GPIO pin Output Level */
  HAL_GPIO_WritePin(BIAS_EN_GPIO_Port, BIAS_EN_Pin, GPIO_PIN_RESET);

  /*Configure GPIO pin Output Level */
  HAL_GPIO_WritePin(GPIOB, DIB_IRQ_Pin|DAC_CS_DUAL_Pin|ADC_CLK_Pin, GPIO_PIN_SET);

  /*Configure GPIO pin Output Level */
  HAL_GPIO_WritePin(GPIOG, IN_CTRL7_Pin|IN_CTRL6_Pin|IN_CTRL5_Pin|IN_CTRL4_Pin
                          |IN_CTRL3_Pin|IN_CTRL2_Pin|ISEL_R_3_Pin|ISEL_S_3_Pin
                          |USEL100_1_Pin|USEL20_1_Pin|USEL1_1_Pin|ISEL_1_Pin, GPIO_PIN_RESET);

  /*Configure GPIO pin Output Level */
  HAL_GPIO_WritePin(ADC_CS_GPIO_Port, ADC_CS_Pin, GPIO_PIN_SET);

  /*Configure GPIO pin Output Level */
  HAL_GPIO_WritePin(GPIOD, USEL20_3_Pin|USEL1_3_Pin|ADIB1_SW_Pin|ISEL_MID_3_Pin
                          |ISEL_LOW_3_Pin|ISEL10_R_3_Pin|ISEL10_S_3_Pin, GPIO_PIN_RESET);

  /*Configure GPIO pins : DIN4_Pin DIN3_Pin DIN2_Pin DIB_SYNC_Pin
                           DIN6_Pin DIN5_Pin */
  GPIO_InitStruct.Pin = DIN4_Pin|DIN3_Pin|DIN2_Pin|DIB_SYNC_Pin
                          |DIN6_Pin|DIN5_Pin;
  GPIO_InitStruct.Mode = GPIO_MODE_INPUT;
  GPIO_InitStruct.Pull = GPIO_NOPULL;
  HAL_GPIO_Init(GPIOE, &GPIO_InitStruct);

  /*Configure GPIO pins : USEL1_4_Pin USEL20_4_Pin ISEL_2_Pin ISEL10_R_4_Pin
                           ISEL_LOW_4_Pin ISEL_MID_4_Pin DOUT4_Pin DOUT5_Pin
                           IN_CTRL1_Pin IN_CTRL0_Pin */
  GPIO_InitStruct.Pin = USEL1_4_Pin|USEL20_4_Pin|ISEL_2_Pin|ISEL10_R_4_Pin
                          |ISEL_LOW_4_Pin|ISEL_MID_4_Pin|DOUT4_Pin|DOUT5_Pin
                          |IN_CTRL1_Pin|IN_CTRL0_Pin;
  GPIO_InitStruct.Mode = GPIO_MODE_OUTPUT_PP;
  GPIO_InitStruct.Pull = GPIO_NOPULL;
  GPIO_InitStruct.Speed = GPIO_SPEED_FREQ_LOW;
  HAL_GPIO_Init(GPIOC, &GPIO_InitStruct);

  /*Configure GPIO pins : USEL1_2_Pin USEL20_2_Pin USEL100_2_Pin ISEL_S_4_Pin
                           ISEL_R_4_Pin ISEL10_S_4_Pin DAC_CS_1_Pin DAC_CLR_1_Pin
                           DAC_CS_2_Pin DAC_CLR_2_Pin */
  GPIO_InitStruct.Pin = USEL1_2_Pin|USEL20_2_Pin|USEL100_2_Pin|ISEL_S_4_Pin
                          |ISEL_R_4_Pin|ISEL10_S_4_Pin|DAC_CS_1_Pin|DAC_CLR_1_Pin
                          |DAC_CS_2_Pin|DAC_CLR_2_Pin;
  GPIO_InitStruct.Mode = GPIO_MODE_OUTPUT_PP;
  GPIO_InitStruct.Pull = GPIO_NOPULL;
  GPIO_InitStruct.Speed = GPIO_SPEED_FREQ_LOW;
  HAL_GPIO_Init(GPIOF, &GPIO_InitStruct);

  /*Configure GPIO pins : DOUT0_Pin DOUT1_Pin DOUT2_Pin DOUT3_Pin
                           DOUT_EN_Pin ADIB2_SW_Pin ADC_CS_Pin */
  GPIO_InitStruct.Pin = DOUT0_Pin|DOUT1_Pin|DOUT2_Pin|DOUT3_Pin
                          |DOUT_EN_Pin|ADIB2_SW_Pin|ADC_CS_Pin;
  GPIO_InitStruct.Mode = GPIO_MODE_OUTPUT_PP;
  GPIO_InitStruct.Pull = GPIO_NOPULL;
  GPIO_InitStruct.Speed = GPIO_SPEED_FREQ_LOW;
  HAL_GPIO_Init(GPIOA, &GPIO_InitStruct);

  /*Configure GPIO pin : DIN7_Pin */
  GPIO_InitStruct.Pin = DIN7_Pin;
  GPIO_InitStruct.Mode = GPIO_MODE_INPUT;
  GPIO_InitStruct.Pull = GPIO_NOPULL;
  HAL_GPIO_Init(DIN7_GPIO_Port, &GPIO_InitStruct);

  /*Configure GPIO pins : DOUT6_Pin DOUT7_Pin DIB_IRQ_Pin DAC_CS_DUAL_Pin
                           ADC_START_Pin ADC_CLK_Pin SLOW_DIN_1_Pin SLOW_DIN_0_Pin */
  GPIO_InitStruct.Pin = DOUT6_Pin|DOUT7_Pin|DIB_IRQ_Pin|DAC_CS_DUAL_Pin
                          |ADC_START_Pin|ADC_CLK_Pin|SLOW_DIN_1_Pin|SLOW_DIN_0_Pin;
  GPIO_InitStruct.Mode = GPIO_MODE_OUTPUT_PP;
  GPIO_InitStruct.Pull = GPIO_NOPULL;
  GPIO_InitStruct.Speed = GPIO_SPEED_FREQ_LOW;
  HAL_GPIO_Init(GPIOB, &GPIO_InitStruct);

  /*Configure GPIO pin : DAC_CLR_SEL_1_Pin */
  GPIO_InitStruct.Pin = DAC_CLR_SEL_1_Pin;
  GPIO_InitStruct.Mode = GPIO_MODE_OUTPUT_PP;
  GPIO_InitStruct.Pull = GPIO_NOPULL;
  GPIO_InitStruct.Speed = GPIO_SPEED_FREQ_VERY_HIGH;
  HAL_GPIO_Init(DAC_CLR_SEL_1_GPIO_Port, &GPIO_InitStruct);

  /*Configure GPIO pin : DAC_CLR_SEL_2_Pin */
  GPIO_InitStruct.Pin = DAC_CLR_SEL_2_Pin;
  GPIO_InitStruct.Mode = GPIO_MODE_IT_RISING;
  GPIO_InitStruct.Pull = GPIO_PULLUP;
  HAL_GPIO_Init(DAC_CLR_SEL_2_GPIO_Port, &GPIO_InitStruct);

  /*Configure GPIO pins : DOUT_FAULT_Pin ADIB2_ID0_Pin */
  GPIO_InitStruct.Pin = DOUT_FAULT_Pin|ADIB2_ID0_Pin;
  GPIO_InitStruct.Mode = GPIO_MODE_INPUT;
  GPIO_InitStruct.Pull = GPIO_PULLUP;
  HAL_GPIO_Init(GPIOG, &GPIO_InitStruct);

  /*Configure GPIO pin : BIAS_EN_Pin */
  GPIO_InitStruct.Pin = BIAS_EN_Pin;
  GPIO_InitStruct.Mode = GPIO_MODE_OUTPUT_PP;
  GPIO_InitStruct.Pull = GPIO_NOPULL;
  GPIO_InitStruct.Speed = GPIO_SPEED_FREQ_LOW;
  HAL_GPIO_Init(BIAS_EN_GPIO_Port, &GPIO_InitStruct);

  /*Configure GPIO pins : AFE_ID1_Pin AFE_ID0_Pin */
  GPIO_InitStruct.Pin = AFE_ID1_Pin|AFE_ID0_Pin;
  GPIO_InitStruct.Mode = GPIO_MODE_INPUT;
  GPIO_InitStruct.Pull = GPIO_PULLUP;
  HAL_GPIO_Init(GPIOE, &GPIO_InitStruct);

  /*Configure GPIO pin : DAC_ALARM_Pin */
  GPIO_InitStruct.Pin = DAC_ALARM_Pin;
  GPIO_InitStruct.Mode = GPIO_MODE_IT_RISING;
  GPIO_InitStruct.Pull = GPIO_PULLUP;
  HAL_GPIO_Init(DAC_ALARM_GPIO_Port, &GPIO_InitStruct);

  /*Configure GPIO pins : ADIB1_ID2_Pin ADIB1_ID1_Pin ADIB1_ID0_Pin ADIB2_ID2_Pin
                           ADIB2_ID1_Pin */
  GPIO_InitStruct.Pin = ADIB1_ID2_Pin|ADIB1_ID1_Pin|ADIB1_ID0_Pin|ADIB2_ID2_Pin
                          |ADIB2_ID1_Pin;
  GPIO_InitStruct.Mode = GPIO_MODE_INPUT;
  GPIO_InitStruct.Pull = GPIO_PULLUP;
  HAL_GPIO_Init(GPIOD, &GPIO_InitStruct);

  /*Configure GPIO pins : IN_CTRL7_Pin IN_CTRL6_Pin IN_CTRL5_Pin IN_CTRL4_Pin
                           IN_CTRL3_Pin IN_CTRL2_Pin ISEL_R_3_Pin ISEL_S_3_Pin
                           USEL100_1_Pin USEL20_1_Pin USEL1_1_Pin ISEL_1_Pin */
  GPIO_InitStruct.Pin = IN_CTRL7_Pin|IN_CTRL6_Pin|IN_CTRL5_Pin|IN_CTRL4_Pin
                          |IN_CTRL3_Pin|IN_CTRL2_Pin|ISEL_R_3_Pin|ISEL_S_3_Pin
                          |USEL100_1_Pin|USEL20_1_Pin|USEL1_1_Pin|ISEL_1_Pin;
  GPIO_InitStruct.Mode = GPIO_MODE_OUTPUT_PP;
  GPIO_InitStruct.Pull = GPIO_NOPULL;
  GPIO_InitStruct.Speed = GPIO_SPEED_FREQ_LOW;
  HAL_GPIO_Init(GPIOG, &GPIO_InitStruct);

  /*Configure GPIO pin : SD_DETECT_Pin */
  GPIO_InitStruct.Pin = SD_DETECT_Pin;
  GPIO_InitStruct.Mode = GPIO_MODE_INPUT;
  GPIO_InitStruct.Pull = GPIO_PULLUP;
  HAL_GPIO_Init(SD_DETECT_GPIO_Port, &GPIO_InitStruct);

  /*Configure GPIO pins : USEL20_3_Pin USEL1_3_Pin ADIB1_SW_Pin ISEL_MID_3_Pin
                           ISEL_LOW_3_Pin ISEL10_R_3_Pin ISEL10_S_3_Pin */
  GPIO_InitStruct.Pin = USEL20_3_Pin|USEL1_3_Pin|ADIB1_SW_Pin|ISEL_MID_3_Pin
                          |ISEL_LOW_3_Pin|ISEL10_R_3_Pin|ISEL10_S_3_Pin;
  GPIO_InitStruct.Mode = GPIO_MODE_OUTPUT_PP;
  GPIO_InitStruct.Pull = GPIO_NOPULL;
  GPIO_InitStruct.Speed = GPIO_SPEED_FREQ_LOW;
  HAL_GPIO_Init(GPIOD, &GPIO_InitStruct);

  /*Configure GPIO pin : ADC_DRDY_Pin */
  GPIO_InitStruct.Pin = ADC_DRDY_Pin;
  GPIO_InitStruct.Mode = GPIO_MODE_IT_FALLING;
  GPIO_InitStruct.Pull = GPIO_PULLUP;
  HAL_GPIO_Init(ADC_DRDY_GPIO_Port, &GPIO_InitStruct);

  /* EXTI interrupt init*/
  HAL_NVIC_SetPriority(EXTI15_10_IRQn, 0, 0);
  HAL_NVIC_EnableIRQ(EXTI15_10_IRQn);

}

void Error_Handler(void)
{
}

/************************ (C) COPYRIGHT STMicroelectronics *****END OF FILE****/
